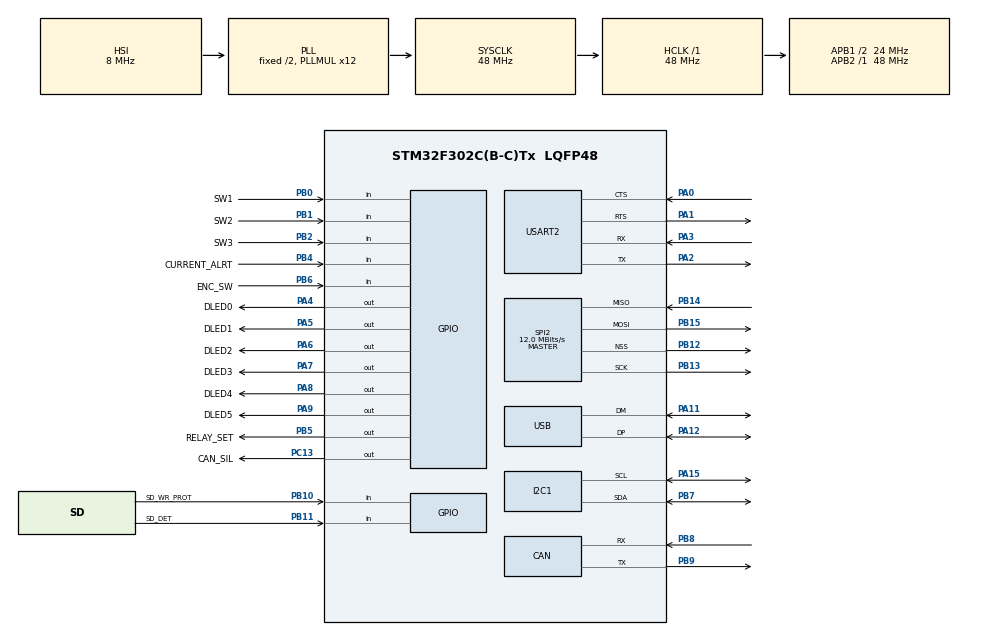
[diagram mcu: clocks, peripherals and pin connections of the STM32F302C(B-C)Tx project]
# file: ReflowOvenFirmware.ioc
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CAN.BS1=CAN_BS1_1TQ
CAN.BS2=CAN_BS2_1TQ
CAN.CalculateTimeQuantum=666.6666666666666
FREERTOS.Tasks01=defaultTask,0,128,StartDefaultTask,Default,NULL,Dynamic,NULL,NULL
Mcu.Family=STM32F3
Mcu.Name=STM32F302C(B-C)Tx
Mcu.Package=LQFP48
NVIC.PriorityGroup=NVIC_PRIORITYGROUP_4
NVIC.TIM1_UP_TIM16_IRQn=true\:0\:0\:false\:false\:true\:false\:false\:true
NVIC.TimeBase=TIM1_UP_TIM16_IRQn
NVIC.TimeBaseIP=TIM1
PA0.Mode=CTS_RTS
PA0.Signal=USART2_CTS
PA1.Mode=CTS_RTS
PA1.Signal=USART2_RTS
PA11.Mode=Device
PA11.Signal=USB_DM
PA12.Mode=Device
PA12.Signal=USB_DP
PA13.Mode=Trace_Asynchronous_SW
PA13.Signal=SYS_JTMS-SWDIO
PA14.Mode=Trace_Asynchronous_SW
PA14.Signal=SYS_JTCK-SWCLK
PA15.Mode=SMBus-two-wire-Interface
PA15.Signal=I2C1_SCL
PA2.Mode=Asynchronous
PA2.Signal=USART2_TX
PA3.Mode=Asynchronous
PA3.Signal=USART2_RX
PA4.GPIO_Label=DLED0
PA4.Signal=GPIO_Output
PA5.GPIO_Label=DLED1
PA5.Signal=GPIO_Output
PA6.GPIO_Label=DLED2
PA6.Signal=GPIO_Output
PA7.GPIO_Label=DLED3
PA7.Signal=GPIO_Output
PA8.GPIO_Label=DLED4
PA8.Signal=GPIO_Output
PA9.GPIO_Label=DLED5
PA9.Signal=GPIO_Output
PB0.GPIO_Label=SW1
PB0.Signal=GPIO_Input
PB1.GPIO_Label=SW2
PB1.Signal=GPIO_Input
PB10.GPIO_Label=SD_WR_PROT
PB10.Signal=GPIO_Input
PB11.GPIO_Label=SD_DET
PB11.Signal=GPIO_Input
PB12.Mode=NSS_Signal_Hard_Output
PB12.Signal=SPI2_NSS
PB13.Mode=Full_Duplex_Master
PB13.Signal=SPI2_SCK
PB14.Mode=Full_Duplex_Master
PB14.Signal=SPI2_MISO
PB15.Mode=Full_Duplex_Master
PB15.Signal=SPI2_MOSI
PB2.GPIO_Label=SW3
PB2.Signal=GPIO_Input
PB3.Mode=Trace_Asynchronous_SW
PB3.Signal=SYS_JTDO-TRACESWO
PB4.GPIO_Label=CURRENT_ALRT
PB4.Signal=GPIO_Input
PB5.GPIO_Label=RELAY_SET
PB5.Signal=GPIO_Output
PB6.GPIO_Label=ENC_SW
PB6.Signal=GPIO_Input
PB7.Mode=SMBus-two-wire-Interface
PB7.Signal=I2C1_SDA
PB8.Mode=Master
PB8.Signal=CAN_RX
PB9.Mode=Master
PB9.Signal=CAN_TX
PC13.GPIO_Label=CAN_SIL
PC13.Signal=GPIO_Output
PF0-OSC_IN.Mode=HSE-External-Clock-Source
PF0-OSC_IN.Signal=RCC_OSC_IN
ProjectManager.HeapSize=0x200
ProjectManager.StackSize=0x400
ProjectManager.TargetToolchain=Makefile
RCC.AHBFreq_Value=48000000
RCC.APB1CLKDivider=RCC_HCLK_DIV2
RCC.APB1Freq_Value=24000000
RCC.APB1TimFreq_Value=48000000
RCC.APB2Freq_Value=48000000
RCC.APB2TimFreq_Value=48000000
RCC.CortexFreq_Value=48000000
RCC.HCLKFreq_Value=48000000
RCC.HSE_VALUE=32000000
RCC.HSI_VALUE=8000000
RCC.LSE_VALUE=32768
RCC.PLLMUL=RCC_PLL_MUL12
RCC.PLLSourceVirtualString=RCC_PLLSOURCE_HSI
RCC.RCC_PLLsource_Clock_Source_FROM_HSE=RCC_HSE_PREDIV_DIV2
RCC.SYSCLKFreq_VALUE=48000000
RCC.SYSCLKSourceVirtual=RCC_SYSCLKSOURCE_PLLCLK
RCC.USBFreq_Value=48000000
SPI2.BaudRatePrescaler=SPI_BAUDRATEPRESCALER_2
SPI2.CalculateBaudRate=12.0 MBits/s
SPI2.Direction=SPI_DIRECTION_2LINES
SPI2.Mode=SPI_MODE_MASTER
SPI2.VirtualNSS=VM_NSSHARD
SPI2.VirtualType=VM_MASTER
USART2.VirtualMode-Asynchronous=VM_ASYNC
VP_FREERTOS_VS_CMSIS_V1.Mode=CMSIS_V1
VP_SYS_VS_tim1.Mode=TIM1
board=custom

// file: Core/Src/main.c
/* USER CODE BEGIN Header */
/**
  ******************************************************************************
  * @file           : main.c
  * @brief          : Main program body
  ******************************************************************************
  * @attention
  *
  * <h2><center>&copy; Copyright (c) 2020 STMicroelectronics.
  * All rights reserved.</center></h2>
  *
  * This software component is licensed by ST under Ultimate Liberty license
  * SLA0044, the "License"; You may not use this file except in compliance with
  * the License. You may obtain a copy of the License at:
  *                             www.st.com/SLA0044
  *
  ******************************************************************************
  */
/* USER CODE END Header */
#include "main.h"
#include "cmsis_os.h"

/* USER CODE BEGIN Includes */
#include "INA226_Driver.h"
#include "MCP96RL01T_Driver.h"
#include "SDCard_Driver.h"
#include "PCF8551ATT_Driver.h"
#include "TCA9534_Driver.h"
/* USER CODE END Includes */

CAN_HandleTypeDef hcan;

SMBUS_HandleTypeDef hsmbus1;

SPI_HandleTypeDef hspi2;

UART_HandleTypeDef huart2;

PCD_HandleTypeDef hpcd_USB_FS;

osThreadId defaultTaskHandle;

void SystemClock_Config(void);
static void MX_GPIO_Init(void);
static void MX_CAN_Init(void);
static void MX_I2C1_SMBUS_Init(void);
static void MX_SPI2_Init(void);
static void MX_USART2_UART_Init(void);
static void MX_USB_PCD_Init(void);
void StartDefaultTask(void const * argument);

int main(void)
{

  /* MCU Configuration--------------------------------------------------------*/

  /* Reset of all peripherals, Initializes the Flash interface and the Systick. */
  HAL_Init();

  /* Configure the system clock */
  SystemClock_Config();

  /* Initialize all configured peripherals */
  MX_GPIO_Init();
  MX_CAN_Init();
  MX_I2C1_SMBUS_Init();
  MX_SPI2_Init();
  MX_USART2_UART_Init();
  MX_USB_PCD_Init();

  /* Create the thread(s) */
  /* definition and creation of defaultTask */
  osThreadDef(defaultTask, StartDefaultTask, osPriorityNormal, 0, 128);
  defaultTaskHandle = osThreadCreate(osThread(defaultTask), NULL);

  /* Start scheduler */
  osKernelStart();

  /* We should never get here as control is now taken by the scheduler */
  /* Infinite loop */
  while (1)
  {

  }
}

void SystemClock_Config(void)
{
  RCC_OscInitTypeDef RCC_OscInitStruct = {0};
  RCC_ClkInitTypeDef RCC_ClkInitStruct = {0};
  RCC_PeriphCLKInitTypeDef PeriphClkInit = {0};

  /** Initializes the RCC Oscillators according to the specified parameters
  * in the RCC_OscInitTypeDef structure.
  */
  RCC_OscInitStruct.OscillatorType = RCC_OSCILLATORTYPE_HSI;
  RCC_OscInitStruct.HSIState = RCC_HSI_ON;
  RCC_OscInitStruct.HSICalibrationValue = RCC_HSICALIBRATION_DEFAULT;
  RCC_OscInitStruct.PLL.PLLState = RCC_PLL_ON;
  RCC_OscInitStruct.PLL.PLLSource = RCC_PLLSOURCE_HSI;
  RCC_OscInitStruct.PLL.PLLMUL = RCC_PLL_MUL12;
  if (HAL_RCC_OscConfig(&RCC_OscInitStruct) != HAL_OK)
  {
    Error_Handler();
  }
  /** Initializes the CPU, AHB and APB buses clocks
  */
  RCC_ClkInitStruct.ClockType = RCC_CLOCKTYPE_HCLK|RCC_CLOCKTYPE_SYSCLK
                              |RCC_CLOCKTYPE_PCLK1|RCC_CLOCKTYPE_PCLK2;
  RCC_ClkInitStruct.SYSCLKSource = RCC_SYSCLKSOURCE_PLLCLK;
  RCC_ClkInitStruct.AHBCLKDivider = RCC_SYSCLK_DIV1;
  RCC_ClkInitStruct.APB1CLKDivider = RCC_HCLK_DIV2;
  RCC_ClkInitStruct.APB2CLKDivider = RCC_HCLK_DIV1;

  if (HAL_RCC_ClockConfig(&RCC_ClkInitStruct, FLASH_LATENCY_1) != HAL_OK)
  {
    Error_Handler();
  }
  PeriphClkInit.PeriphClockSelection = RCC_PERIPHCLK_USB|RCC_PERIPHCLK_USART2
                              |RCC_PERIPHCLK_I2C1;
  PeriphClkInit.Usart2ClockSelection = RCC_USART2CLKSOURCE_PCLK1;
  PeriphClkInit.I2c1ClockSelection = RCC_I2C1CLKSOURCE_HSI;
  PeriphClkInit.USBClockSelection = RCC_USBCLKSOURCE_PLL;
  if (HAL_RCCEx_PeriphCLKConfig(&PeriphClkInit) != HAL_OK)
  {
    Error_Handler();
  }
}

static void MX_CAN_Init(void)
{

  hcan.Instance = CAN;
  hcan.Init.Prescaler = 16;
  hcan.Init.Mode = CAN_MODE_NORMAL;
  hcan.Init.SyncJumpWidth = CAN_SJW_1TQ;
  hcan.Init.TimeSeg1 = CAN_BS1_1TQ;
  hcan.Init.TimeSeg2 = CAN_BS2_1TQ;
  hcan.Init.TimeTriggeredMode = DISABLE;
  hcan.Init.AutoBusOff = DISABLE;
  hcan.Init.AutoWakeUp = DISABLE;
  hcan.Init.AutoRetransmission = DISABLE;
  hcan.Init.ReceiveFifoLocked = DISABLE;
  hcan.Init.TransmitFifoPriority = DISABLE;
  if (HAL_CAN_Init(&hcan) != HAL_OK)
  {
    Error_Handler();
  }

}

static void MX_I2C1_SMBUS_Init(void)
{

  hsmbus1.Instance = I2C1;
  hsmbus1.Init.Timing = 0x2000090E;
  hsmbus1.Init.AnalogFilter = SMBUS_ANALOGFILTER_ENABLE;
  hsmbus1.Init.OwnAddress1 = 2;
  hsmbus1.Init.AddressingMode = SMBUS_ADDRESSINGMODE_7BIT;
  hsmbus1.Init.DualAddressMode = SMBUS_DUALADDRESS_DISABLE;
  hsmbus1.Init.OwnAddress2 = 0;
  hsmbus1.Init.OwnAddress2Masks = SMBUS_OA2_NOMASK;
  hsmbus1.Init.GeneralCallMode = SMBUS_GENERALCALL_DISABLE;
  hsmbus1.Init.NoStretchMode = SMBUS_NOSTRETCH_DISABLE;
  hsmbus1.Init.PacketErrorCheckMode = SMBUS_PEC_DISABLE;
  hsmbus1.Init.PeripheralMode = SMBUS_PERIPHERAL_MODE_SMBUS_SLAVE;
  hsmbus1.Init.SMBusTimeout = 0x00008061;
  if (HAL_SMBUS_Init(&hsmbus1) != HAL_OK)
  {
    Error_Handler();
  }

}

static void MX_SPI2_Init(void)
{

  /* SPI2 parameter configuration*/
  hspi2.Instance = SPI2;
  hspi2.Init.Mode = SPI_MODE_MASTER;
  hspi2.Init.Direction = SPI_DIRECTION_2LINES;
  hspi2.Init.DataSize = SPI_DATASIZE_4BIT;
  hspi2.Init.CLKPolarity = SPI_POLARITY_LOW;
  hspi2.Init.CLKPhase = SPI_PHASE_1EDGE;
  hspi2.Init.NSS = SPI_NSS_HARD_OUTPUT;
  hspi2.Init.BaudRatePrescaler = SPI_BAUDRATEPRESCALER_2;
  hspi2.Init.FirstBit = SPI_FIRSTBIT_MSB;
  hspi2.Init.TIMode = SPI_TIMODE_DISABLE;
  hspi2.Init.CRCCalculation = SPI_CRCCALCULATION_DISABLE;
  hspi2.Init.CRCPolynomial = 7;
  hspi2.Init.CRCLength = SPI_CRC_LENGTH_DATASIZE;
  hspi2.Init.NSSPMode = SPI_NSS_PULSE_ENABLE;
  if (HAL_SPI_Init(&hspi2) != HAL_OK)
  {
    Error_Handler();
  }

}

static void MX_USART2_UART_Init(void)
{

  huart2.Instance = USART2;
  huart2.Init.BaudRate = 38400;
  huart2.Init.WordLength = UART_WORDLENGTH_8B;
  huart2.Init.StopBits = UART_STOPBITS_1;
  huart2.Init.Parity = UART_PARITY_NONE;
  huart2.Init.Mode = UART_MODE_TX_RX;
  huart2.Init.HwFlowCtl = UART_HWCONTROL_RTS_CTS;
  huart2.Init.OverSampling = UART_OVERSAMPLING_16;
  huart2.Init.OneBitSampling = UART_ONE_BIT_SAMPLE_DISABLE;
  huart2.AdvancedInit.AdvFeatureInit = UART_ADVFEATURE_NO_INIT;
  if (HAL_UART_Init(&huart2) != HAL_OK)
  {
    Error_Handler();
  }

}

static void MX_USB_PCD_Init(void)
{

  hpcd_USB_FS.Instance = USB;
  hpcd_USB_FS.Init.dev_endpoints = 8;
  hpcd_USB_FS.Init.speed = PCD_SPEED_FULL;
  hpcd_USB_FS.Init.phy_itface = PCD_PHY_EMBEDDED;
  hpcd_USB_FS.Init.low_power_enable = DISABLE;
  hpcd_USB_FS.Init.battery_charging_enable = DISABLE;
  if (HAL_PCD_Init(&hpcd_USB_FS) != HAL_OK)
  {
    Error_Handler();
  }

}

static void MX_GPIO_Init(void)
{
  GPIO_InitTypeDef GPIO_InitStruct = {0};

  /* GPIO Ports Clock Enable */
  __HAL_RCC_GPIOC_CLK_ENABLE();
  __HAL_RCC_GPIOF_CLK_ENABLE();
  __HAL_RCC_GPIOA_CLK_ENABLE();
  __HAL_RCC_GPIOB_CLK_ENABLE();

  /*Configure GPIO pin Output Level */
  HAL_GPIO_WritePin(CAN_SIL_GPIO_Port, CAN_SIL_Pin, GPIO_PIN_RESET);

  /*Configure GPIO pin Output Level */
  HAL_GPIO_WritePin(GPIOA, DLED0_Pin|DLED1_Pin|DLED2_Pin|DLED3_Pin
                          |DLED4_Pin|DLED5_Pin, GPIO_PIN_RESET);

  /*Configure GPIO pin Output Level */
  HAL_GPIO_WritePin(RELAY_SET_GPIO_Port, RELAY_SET_Pin, GPIO_PIN_RESET);

  /*Configure GPIO pin : CAN_SIL_Pin */
  GPIO_InitStruct.Pin = CAN_SIL_Pin;
  GPIO_InitStruct.Mode = GPIO_MODE_OUTPUT_PP;
  GPIO_InitStruct.Pull = GPIO_NOPULL;
  GPIO_InitStruct.Speed = GPIO_SPEED_FREQ_LOW;
  HAL_GPIO_Init(CAN_SIL_GPIO_Port, &GPIO_InitStruct);

  /*Configure GPIO pins : DLED0_Pin DLED1_Pin DLED2_Pin DLED3_Pin
                           DLED4_Pin DLED5_Pin */
  GPIO_InitStruct.Pin = DLED0_Pin|DLED1_Pin|DLED2_Pin|DLED3_Pin
                          |DLED4_Pin|DLED5_Pin;
  GPIO_InitStruct.Mode = GPIO_MODE_OUTPUT_PP;
  GPIO_InitStruct.Pull = GPIO_NOPULL;
  GPIO_InitStruct.Speed = GPIO_SPEED_FREQ_LOW;
  HAL_GPIO_Init(GPIOA, &GPIO_InitStruct);

  /*Configure GPIO pins : SW1_Pin SW2_Pin SW3_Pin SD_WR_PROT_Pin
                           SD_DET_Pin CURRENT_ALRT_Pin ENC_SW_Pin */
  GPIO_InitStruct.Pin = SW1_Pin|SW2_Pin|SW3_Pin|SD_WR_PROT_Pin
                          |SD_DET_Pin|CURRENT_ALRT_Pin|ENC_SW_Pin;
  GPIO_InitStruct.Mode = GPIO_MODE_INPUT;
  GPIO_InitStruct.Pull = GPIO_NOPULL;
  HAL_GPIO_Init(GPIOB, &GPIO_InitStruct);

  /*Configure GPIO pin : RELAY_SET_Pin */
  GPIO_InitStruct.Pin = RELAY_SET_Pin;
  GPIO_InitStruct.Mode = GPIO_MODE_OUTPUT_PP;
  GPIO_InitStruct.Pull = GPIO_NOPULL;
  GPIO_InitStruct.Speed = GPIO_SPEED_FREQ_LOW;
  HAL_GPIO_Init(RELAY_SET_GPIO_Port, &GPIO_InitStruct);

}

void StartDefaultTask(void const * argument)
{
  for(;;)
  {
    osDelay(1);
  }
}

void HAL_TIM_PeriodElapsedCallback(TIM_HandleTypeDef *htim)
{
  if (htim->Instance == TIM1) {
    HAL_IncTick();
  }
}

void Error_Handler(void)
{
}

/************************ (C) COPYRIGHT STMicroelectronics *****END OF FILE****/
